# TOP_ESM_TOP_ESM register map
Vendor: Texas Instruments
Peripheral module from a debugger description file (folder AM263).
Registers are 8-bit, read-only, reset 0x0 unless marked. A register's access mark holds for its fields unless they carry their own. Offsets are as the file gives them; lines under a group give offsets from that group; [hi:lo] are bit positions; {n}, {i} and the like mark numbered series; 'fields as' and 'values as' point back to an identical list; <NAME> marks a mode.

## TOP_ESM_TOP_ESM
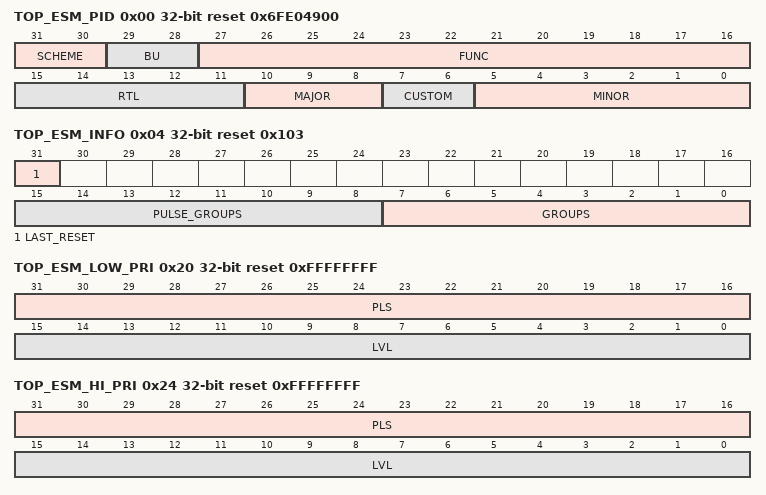
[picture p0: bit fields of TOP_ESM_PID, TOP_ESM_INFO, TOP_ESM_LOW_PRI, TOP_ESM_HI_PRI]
0x00 TOP_ESM_PID 32-bit reset 0x6FE04900
  [31:30] SCHEME — PID register scheme
  [29:28] BU — Business Unit: 10 = Processors
  [27:16] FUNC — Module ID
  [15:11] RTL — RTL revision. Will vary depending on release.
  [10:8] MAJOR — Major revision
  [7:6] CUSTOM
  [5:0] MINOR — Minor revision
0x04 TOP_ESM_INFO 32-bit reset 0x103
  [31] LAST_RESET — Indicates the Source of the last Reset
  [15:8] PULSE_GROUPS — Number of Pulse Error Groups
  [7:0] GROUPS — Total number of Error Groups
0x08 TOP_ESM_EN rw
  [3:0] KEY — Global Enable
0x0C TOP_ESM_SFT_RST wo
  [3:0] KEY — Global Soft Reset
0x10 TOP_ESM_ERR_RAW rw
  [2:0] STS — This is the raw status for config errors
0x14 TOP_ESM_ERR_STS rw
  [2:0] MSK — This is the masked status/clear for config errors
0x18 TOP_ESM_ERR_EN_SET rw
  [2:0] MSK — This is the mask enable set for config errors
0x1C TOP_ESM_ERR_EN_CLR rw
  [2:0] MSK — This is the mask enable clear for config errors
0x20 TOP_ESM_LOW_PRI 32-bit reset 0xFFFFFFFF
  [31:16] PLS — This is the highest priority outstanding low priority pulse interrupt
  [15:0] LVL — This is the highest priority outstanding low priority level interrupt
0x24 TOP_ESM_HI_PRI 32-bit reset 0xFFFFFFFF
  [31:16] PLS — This is the highest priority outstanding high priority pulse interrupt
  [15:0] LVL — This is the highest priority outstanding high priority level interrupt
0x28 TOP_ESM_LOW 32-bit
  [31:0] STS — This is the raw status for config errors
0x2C TOP_ESM_HI 32-bit
  [31:0] STS — This is the raw status for config errors
0x30 TOP_ESM_EOI 16-bit wo
  [10:0] KEY — This is the interrupt being serviced
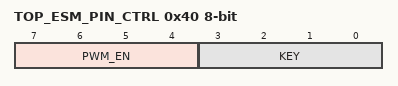
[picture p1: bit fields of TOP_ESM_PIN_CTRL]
0x40 TOP_ESM_PIN_CTRL rw
  [7:4] PWM_EN — PWM enable
  [3:0] KEY — Pin Control Key
0x44 TOP_ESM_PIN_STS size not given
  [0] VAL — Value of the error_pin_n
0x48 TOP_ESM_PIN_CNTR 24-bit
  [23:0] COUNT — Current Counter Value
0x4C TOP_ESM_PIN_CNTR_PRE 24-bit rw
  [23:0] COUNT — Counter Pre-Load Value
0x50 TOP_ESM_PWMH_PIN_CNTR 24-bit
  [23:0] COUNT — Current Counter Value
0x54 TOP_ESM_PWMH_PIN_CNTR_PRE 24-bit rw
  [23:0] COUNT — Counter Pre-Load Value
0x58 TOP_ESM_PWML_PIN_CNTR 24-bit
  [23:0] COUNT — Current Counter Value
0x5C TOP_ESM_PWML_PIN_CNTR_PRE 24-bit rw
  [23:0] COUNT — Counter Pre-Load Value
